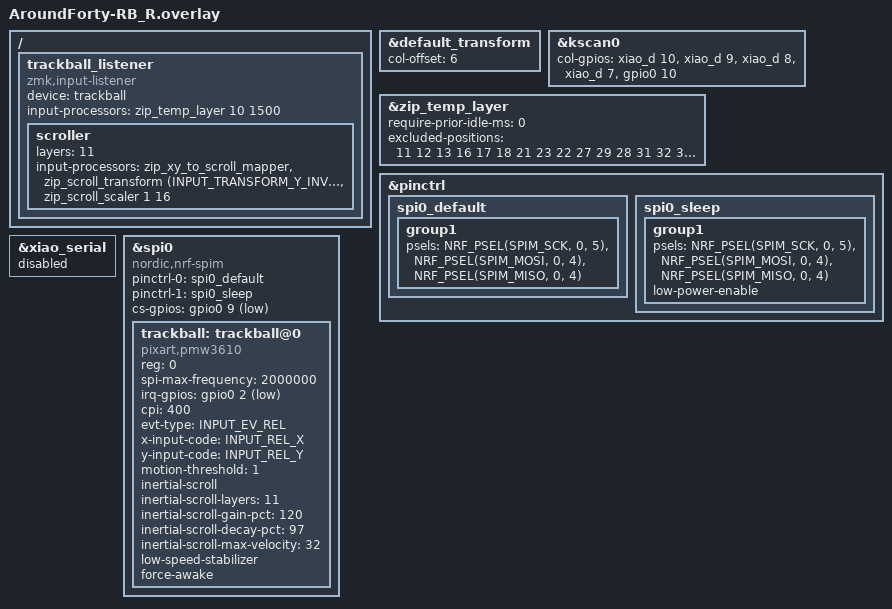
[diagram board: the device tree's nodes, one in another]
#include "AroundForty-RB.dtsi"
#include <dt-bindings/zmk/input_transform.h>
#include <input/processors.dtsi>
#include <zephyr/dt-bindings/input/input-event-codes.h>

&default_transform {
    col-offset = <6>;
};

&kscan0 {
        col-gpios
            = <&xiao_d 10 GPIO_ACTIVE_HIGH>
            , <&xiao_d 9 GPIO_ACTIVE_HIGH> 
            , <&xiao_d 8 GPIO_ACTIVE_HIGH> 
            , <&xiao_d 7 GPIO_ACTIVE_HIGH> 
            , <&gpio0 10 GPIO_ACTIVE_HIGH>
            ;
};

&zip_temp_layer {
    require-prior-idle-ms = <0>;
    excluded-positions = <
        11 // 左手 MB2 (S)
        12 // 左手 MB3 (N)
        13 // 左手 MB1 (T)
        16 // 右手 MB1 (A)
        17 // 右手 MB3 (I)
        18 // 右手 MB2 (U)
        21 23 // 左手 デスクトップ切り替え
        22 // 左手 スクロール (M)
        27 29 // 右手 デスクトップ切り替え
        28 // 右手 スクロール (J)
        31 32 33 34 35 36 37 38 39 40 41 // 最下段・親指キー
    >;
};

/ {
    trackball_listener {
        compatible = "zmk,input-listener";
        device = <&trackball>;
        input-processors = <&zip_temp_layer 10 1500>;

        scroller {
            layers = <11>;
            input-processors = <&zip_xy_to_scroll_mapper>, <&zip_scroll_transform (INPUT_TRANSFORM_Y_INVERT)>, <&zip_scroll_scaler 1 16>;
        };
    };
};

&pinctrl {
    spi0_default: spi0_default {
        group1 {
            psels = <NRF_PSEL(SPIM_SCK, 0, 5)>,
                <NRF_PSEL(SPIM_MOSI, 0, 4)>,
                <NRF_PSEL(SPIM_MISO, 0, 4)>;
        };
    };

    spi0_sleep: spi0_sleep {
        group1 {
            psels = <NRF_PSEL(SPIM_SCK, 0, 5)>,
                <NRF_PSEL(SPIM_MOSI, 0, 4)>,
                <NRF_PSEL(SPIM_MISO, 0, 4)>;
            low-power-enable;
        };
    };
};

&xiao_serial { status = "disabled"; };

&spi0 {
    status = "okay";
    compatible = "nordic,nrf-spim";
    pinctrl-0 = <&spi0_default>;
    pinctrl-1 = <&spi0_sleep>;
    pinctrl-names = "default", "sleep";
    cs-gpios = <&gpio0 9 GPIO_ACTIVE_LOW>;

    trackball: trackball@0 {
        status = "okay";
        compatible = "pixart,pmw3610";
        reg = <0>;
        spi-max-frequency = <2000000>;
        irq-gpios = <&gpio0 2 (GPIO_ACTIVE_LOW | GPIO_PULL_UP)>;
        cpi = <400>;
        evt-type = <INPUT_EV_REL>;
        x-input-code = <INPUT_REL_X>;
        y-input-code = <INPUT_REL_Y>;
        motion-threshold = <1>;
        inertial-scroll;
        inertial-scroll-layers = <11>;
        inertial-scroll-gain-pct = <120>;
        inertial-scroll-decay-pct = <97>;
        inertial-scroll-max-velocity = <32>;
        low-speed-stabilizer;
        force-awake;
    };
};


